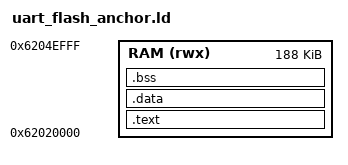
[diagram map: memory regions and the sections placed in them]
ENTRY(_start)

MEMORY
{
    RAM (rwx) : ORIGIN = 0x62020000, LENGTH = 188K
}

SECTIONS
{
    .text : ALIGN(4)
    {
        KEEP(*(.text.entry))
        *(.text .text.*)
        *(.rodata .rodata.*)
        . = ALIGN(4);
    } > RAM

    .data : ALIGN(4)
    {
        *(.data .data.*)
        *(.sdata .sdata.*)
        . = ALIGN(4);
    } > RAM

    .bss (NOLOAD) : ALIGN(4)
    {
        *(.bss .bss.*)
        *(COMMON)
        . = ALIGN(4);
    } > RAM

    /DISCARD/ :
    {
        *(.comment)
        *(.note.*)
        *(.eh_frame*)
    }
}
